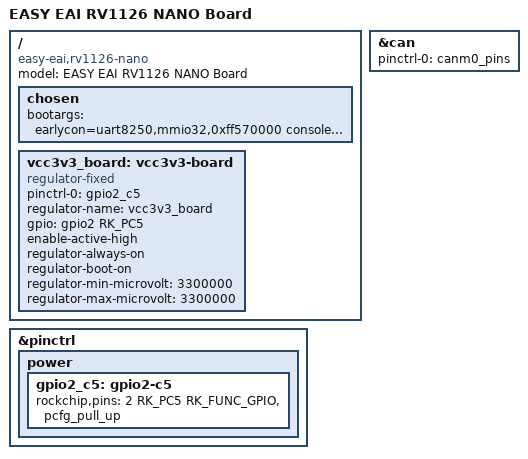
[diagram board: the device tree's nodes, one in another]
// SPDX-License-Identifier: (GPL-2.0+ OR MIT)
/*
 * Copyright (c) 2024 Guangzhou EASY EAI Technology Co., Ltd.
 */
/dts-v1/;
#include "rv1126-core.dtsi"
//#include "rv1126-nano-dummy.dtsi"
#include "rv1126-nano-lmo5inch.dtsi"
#include "rv1126-nano-dual-gc20xx.dtsi"
#include "rv1126-nano-gmac-100m.dtsi"
#include "rv1126-nano-usb-otg.dtsi"
#include "rv1126-nano-usb-host.dtsi"
#include "rv1126-nano-sdmmc.dtsi"
#include "rv1126-nano-sdio-ap6212.dtsi"
#include "rv1126-nano-wdt-gpio.dtsi"
#include "rv1126-nano-adc0-key.dtsi"
#include "rv1126-nano-spi-devices.dtsi"
#include "rv1126-nano-uart.dtsi"
#include "rv1126-nano-pwm.dtsi"

/ {
	model = "EASY EAI RV1126 NANO Board";
	compatible = "easy-eai,rv1126-nano", "rockchip,rv1126";

	chosen {
		bootargs = "earlycon=uart8250,mmio32,0xff570000 console=ttyFIQ0 root=PARTUUID=614e0000-0000 rootwait snd_aloop.index=7";
	};

	vcc3v3_board: vcc3v3-board {
		pinctrl-names = "default";
		pinctrl-0 = <&gpio2_c5>;
		compatible = "regulator-fixed";
		regulator-name = "vcc3v3_board";
		gpio = <&gpio2 RK_PC5 GPIO_ACTIVE_HIGH>;
		enable-active-high;
		regulator-always-on;
		regulator-boot-on;
		regulator-min-microvolt = <3300000>;
		regulator-max-microvolt = <3300000>;
	};
};

&can {
	pinctrl-names = "default";
	pinctrl-0 = <&canm0_pins>;
	status = "okay";
};

&pinctrl {
	power {
		/omit-if-no-ref/
		gpio2_c5: gpio2-c5 {
			rockchip,pins =
				<2 RK_PC5 RK_FUNC_GPIO &pcfg_pull_up>;
		};
	};
};
